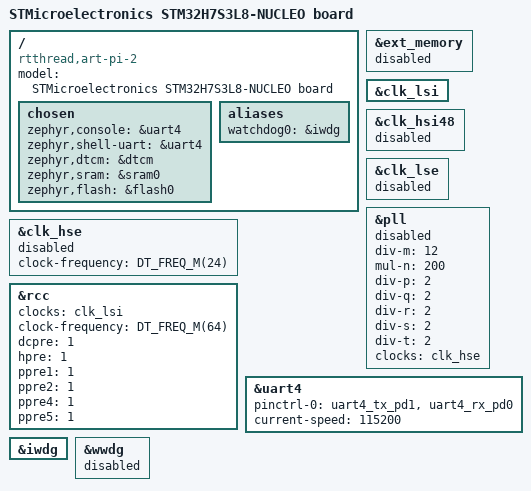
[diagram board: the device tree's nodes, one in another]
/*
 * Copyright (c) 2024 STMicroelectronics
 *
 * SPDX-License-Identifier: Apache-2.0
 */

/dts-v1/;
#include <st/h7rs/stm32h7r7X8.dtsi>
#include <st/h7/stm32h7r7l8hxh-pinctrl.dtsi>
// #include "arduino_r3_connector.dtsi"
#include <zephyr/dt-bindings/input/input-event-codes.h>

/ {
	model = "STMicroelectronics STM32H7S3L8-NUCLEO board";
	compatible = "rtthread,art-pi-2";

	chosen {
		zephyr,console = &uart4;
		zephyr,shell-uart = &uart4;
		zephyr,dtcm = &dtcm;
		zephyr,sram = &sram0;
		zephyr,flash = &flash0;
	};

	// leds: leds {
	// 	compatible = "gpio-leds";
	// 	green_led: led_1 {
	// 		gpios = <&gpiod 10 GPIO_ACTIVE_HIGH>;
	// 		label = "User LD1";
	// 	};
	// 	yellow_led: led_2 {
	// 		gpios = <&gpiod 13 GPIO_ACTIVE_HIGH>;
	// 		label = "User LD2";
	// 	};
	// 	red_led: led_3 {
	// 		gpios = <&gpiob 7 GPIO_ACTIVE_HIGH>;
	// 		label = "User LD3";
	// 	};
	// };

	// gpio_keys {
	// 	compatible = "gpio-keys";
	// 	user_button: button_0 {
	// 		label = "User";
	// 		gpios = <&gpioc 13 GPIO_ACTIVE_HIGH>;
	// 		zephyr,code = <INPUT_KEY_0>;
	// 	};
	// };

	aliases {
		// led0 = &green_led;
		// led1 = &yellow_led;
		// led2 = &red_led;
		// sw0 = &user_button;
		watchdog0 = &iwdg;
	};


};
&ext_memory{
	status = "disabled";
};
&clk_lsi {
	status = "okay";
};

&clk_hsi48 {
	status = "disabled";
};

&clk_hse {
	clock-frequency = <DT_FREQ_M(24)>;
	status = "disabled";
};

&clk_lse {
	status = "disabled";
};

&pll {
	div-m = <12>;
	mul-n = <200>;
	div-p = <2>;
	div-q = <2>;
	div-r = <2>;
	div-s = <2>;
	div-t = <2>;
	clocks = <&clk_hse>;
	status = "disabled";
};

&rcc {
	clocks = <&clk_lsi>;
	clock-frequency = <DT_FREQ_M(64)>;
	dcpre = <1>;
	hpre = <1>;
	ppre1 = <1>;
	ppre2 = <1>;
	ppre4 = <1>;
	ppre5 = <1>;
};

// &usart1 {
// 	pinctrl-0 = <&usart1_tx_pb14 &usart1_rx_pa10>;
// 	pinctrl-names = "default";
// 	current-speed = <115200>;
// 	status = "okay";
// };

&uart4 {
	pinctrl-0 = <&uart4_tx_pd1 &uart4_rx_pd0>;
	pinctrl-names = "default";
	current-speed = <115200>;
	status = "okay";
};

&iwdg {
	status = "okay";
};

&wwdg {
	status = "disabled";
};

// &adc1 {
// 	pinctrl-0 = <&adc1_inp15_pa3>; /* Arduino A0 */
// 	pinctrl-names = "default";
// 	st,adc-clock-source = "SYNC";
// 	st,adc-prescaler = <4>;
// 	status = "okay";
// };

// &spi1 {
// 	status = "okay";
// 	pinctrl-0 = <&spi1_sck_pa5 &spi1_miso_pa6 &spi1_mosi_pb5>;
// 	pinctrl-names = "default";
// 	cs-gpios = <&gpiod 14 (GPIO_ACTIVE_LOW | GPIO_PULL_UP)>;
// };

// &i2c1 {
// 	pinctrl-0 = <&i2c1_scl_pb8 &i2c1_sda_pb9>;
// 	pinctrl-names = "default";
// 	status = "okay";
// 	clock-frequency = <I2C_BITRATE_FAST>;
// };
